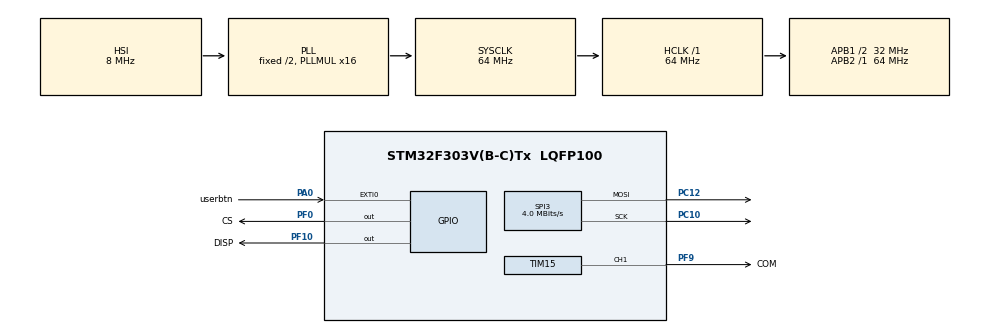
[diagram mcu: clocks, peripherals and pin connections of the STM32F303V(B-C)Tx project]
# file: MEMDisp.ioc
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Mcu.Family=STM32F3
Mcu.Name=STM32F303V(B-C)Tx
Mcu.Package=LQFP100
NVIC.EXTI0_IRQn=true\:0\:0\:false\:false\:true\:true\:true
NVIC.PriorityGroup=NVIC_PRIORITYGROUP_0
PA0.GPIO_Label=userbtn
PA0.Signal=GPXTI0
PA13.Signal=SYS_JTMS-SWDIO
PA14.Signal=SYS_JTCK-SWCLK
PB3.Signal=SYS_JTDO-TRACESWO
PC10.Mode=TX_Only_Simplex_Unidirect_Master
PC10.Signal=SPI3_SCK
PC12.Mode=TX_Only_Simplex_Unidirect_Master
PC12.Signal=SPI3_MOSI
PF0-OSC_IN.GPIO_Label=CS
PF0-OSC_IN.Signal=GPIO_Output
PF10.GPIO_Label=DISP
PF10.Signal=GPIO_Output
PF9.GPIO_Label=COM
PF9.GPIO_Speed=GPIO_SPEED_FREQ_HIGH
PF9.Signal=S_TIM15_CH1
ProjectManager.HeapSize=0x200
ProjectManager.StackSize=0x400
ProjectManager.TargetToolchain=STM32CubeIDE
RCC.AHBFreq_Value=64000000
RCC.APB1CLKDivider=RCC_HCLK_DIV2
RCC.APB1Freq_Value=32000000
RCC.APB1TimFreq_Value=64000000
RCC.APB2Freq_Value=64000000
RCC.APB2TimFreq_Value=64000000
RCC.CortexFreq_Value=64000000
RCC.HCLKFreq_Value=64000000
RCC.HSE_VALUE=8000000
RCC.HSI_VALUE=8000000
RCC.LSE_VALUE=32768
RCC.PLLMUL=RCC_PLL_MUL16
RCC.SYSCLKFreq_VALUE=64000000
RCC.SYSCLKSourceVirtual=RCC_SYSCLKSOURCE_PLLCLK
RCC.USBFreq_Value=64000000
SH.S_TIM15_CH1.0=TIM15_CH1,PWM Generation1 CH1
SPI3.BaudRatePrescaler=SPI_BAUDRATEPRESCALER_8
SPI3.CalculateBaudRate=4.0 MBits/s
SPI3.DataSize=SPI_DATASIZE_8BIT
SPI3.Direction=SPI_DIRECTION_2LINES
SPI3.FirstBit=SPI_FIRSTBIT_MSB
SPI3.Mode=SPI_MODE_MASTER
SPI3.NSSPMode=SPI_NSS_PULSE_DISABLE
SPI3.TIMode=SPI_TIMODE_DISABLE
SPI3.VirtualType=VM_MASTER
TIM15.AutoReloadPreload=TIM_AUTORELOAD_PRELOAD_DISABLE
TIM15.Channel-PWM\ Generation1\ CH1=TIM_CHANNEL_1
TIM15.Period=20 - 1
TIM15.Prescaler=64000-1
VP_TIM15_VS_ClockSourceINT.Mode=Internal
board=STM32F3DISCOVERY

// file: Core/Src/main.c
/* USER CODE BEGIN Header */
/**
  ******************************************************************************
  * @file           : main.c
  * @brief          : Main program body
  ******************************************************************************
  * @attention
  *
  * <h2><center>&copy; Copyright (c) 2020 STMicroelectronics.
  * All rights reserved.</center></h2>
  *
  * This software component is licensed by ST under BSD 3-Clause license,
  * the "License"; You may not use this file except in compliance with the
  * License. You may obtain a copy of the License at:
  *                        opensource.org/licenses/BSD-3-Clause
  *
  ******************************************************************************
  */
/* USER CODE END Header */
#include "main.h"

/* USER CODE BEGIN Includes */
#include "LS027B7DH01.h"
#include "Image.h"
#include "Image2.h"
/* USER CODE END Includes */

/* USER CODE BEGIN PTD */
LS027B7DH01 MemDisp;
/* USER CODE END PTD */

SPI_HandleTypeDef hspi3;

TIM_HandleTypeDef htim15;

/* USER CODE BEGIN PV */
uint8_t swCase,itCall;
/* USER CODE END PV */

void SystemClock_Config(void);
static void MX_GPIO_Init(void);
static void MX_SPI3_Init(void);
static void MX_TIM15_Init(void);

int main(void)
{

  /* MCU Configuration--------------------------------------------------------*/

  /* Reset of all peripherals, Initializes the Flash interface and the Systick. */
  HAL_Init();

  /* Configure the system clock */
  SystemClock_Config();

  /* Initialize all configured peripherals */
  MX_GPIO_Init();
  MX_SPI3_Init();
  MX_TIM15_Init();
  /* USER CODE BEGIN 2 */
  /* Pinout (MCU -> Display)
   * PC10 -> SCLK
   * PC12 -> SI
   * PF0  -> SCS
   * PF9  -> EXTCOMIN
   * PF10 -> DISP
   */
  // ALL GPIO AND BUSES MUST BE INITED BEFORE CALL THIS FUNCTION
  LCD_Init(&MemDisp,&hspi3,GPIOF,CS_Pin,DISP_Pin,&htim15,TIM_CHANNEL_1);
  HAL_Delay(1000);

  /* USER CODE END 2 */

  /* Infinite loop */
  while (1)
  {
	 if(itCall !=0){
	  switch(swCase){

	  	case 0:
	  		  LCD_BufClean();
	  		  LCD_Clean(&MemDisp);
	  		  itCall = 0;
	  		  break;
	  	case 1:
	  		  LCD_LoadFull((uint8_t *)Disney);
	  		  HAL_Delay(100);
	  		  LCD_Update(&MemDisp);
	  		  itCall = 0;
	  		  break;
	  	case 2:
	  		  LCD_Fill(true);
	  		  LCD_Update(&MemDisp);
	  		  itCall = 0;
	  		  break;
	  	case 3:
	  		  LCD_LoadPart((uint8_t *)GawrGura,10,1,30,240); //Sauce : @NotSafeForCode
	  		  HAL_Delay(100);
	  		  LCD_Update(&MemDisp);
	  		  itCall = 0;
	  		  break;
	  	case 4:
	  		  LCD_BufClean();
	  		  LCD_Clean(&MemDisp);
	  		  itCall = 0;
	  		  break;

	  	case 5:
	  		  LCD_Print("This is \nLS027B7DH01 !",21);
	  		  HAL_Delay(10);
	  		  LCD_Update(&MemDisp);
	  		  itCall = 0;
	  		  break;
	  	case 6:
	  		  LCD_Invert();
	  		  LCD_Update(&MemDisp);
	  		  itCall = 0;
	  		  break;
	  	case 7:
	  		  LCD_Print("\nCoded By TinLethax!",21);
	  		  HAL_Delay(10);
	  		  LCD_Update(&MemDisp);
	  		  itCall = 0;
	  		  swCase = 0;
	  		  break;
	  	default:
	  		break;
	  	}
	 }
  }
}

void SystemClock_Config(void)
{
  RCC_OscInitTypeDef RCC_OscInitStruct = {0};
  RCC_ClkInitTypeDef RCC_ClkInitStruct = {0};

  /** Initializes the RCC Oscillators according to the specified parameters
  * in the RCC_OscInitTypeDef structure.
  */
  RCC_OscInitStruct.OscillatorType = RCC_OSCILLATORTYPE_HSI;
  RCC_OscInitStruct.HSIState = RCC_HSI_ON;
  RCC_OscInitStruct.HSICalibrationValue = RCC_HSICALIBRATION_DEFAULT;
  RCC_OscInitStruct.PLL.PLLState = RCC_PLL_ON;
  RCC_OscInitStruct.PLL.PLLSource = RCC_PLLSOURCE_HSI;
  RCC_OscInitStruct.PLL.PLLMUL = RCC_PLL_MUL16;
  if (HAL_RCC_OscConfig(&RCC_OscInitStruct) != HAL_OK)
  {
    Error_Handler();
  }
  /** Initializes the CPU, AHB and APB buses clocks
  */
  RCC_ClkInitStruct.ClockType = RCC_CLOCKTYPE_HCLK|RCC_CLOCKTYPE_SYSCLK
                              |RCC_CLOCKTYPE_PCLK1|RCC_CLOCKTYPE_PCLK2;
  RCC_ClkInitStruct.SYSCLKSource = RCC_SYSCLKSOURCE_PLLCLK;
  RCC_ClkInitStruct.AHBCLKDivider = RCC_SYSCLK_DIV1;
  RCC_ClkInitStruct.APB1CLKDivider = RCC_HCLK_DIV2;
  RCC_ClkInitStruct.APB2CLKDivider = RCC_HCLK_DIV1;

  if (HAL_RCC_ClockConfig(&RCC_ClkInitStruct, FLASH_LATENCY_2) != HAL_OK)
  {
    Error_Handler();
  }
}

static void MX_SPI3_Init(void)
{

  /* SPI3 parameter configuration*/
  hspi3.Instance = SPI3;
  hspi3.Init.Mode = SPI_MODE_MASTER;
  hspi3.Init.Direction = SPI_DIRECTION_2LINES;
  hspi3.Init.DataSize = SPI_DATASIZE_8BIT;
  hspi3.Init.CLKPolarity = SPI_POLARITY_LOW;
  hspi3.Init.CLKPhase = SPI_PHASE_1EDGE;
  hspi3.Init.NSS = SPI_NSS_SOFT;
  hspi3.Init.BaudRatePrescaler = SPI_BAUDRATEPRESCALER_8;
  hspi3.Init.FirstBit = SPI_FIRSTBIT_MSB;
  hspi3.Init.TIMode = SPI_TIMODE_DISABLE;
  hspi3.Init.CRCCalculation = SPI_CRCCALCULATION_DISABLE;
  hspi3.Init.CRCPolynomial = 7;
  hspi3.Init.CRCLength = SPI_CRC_LENGTH_DATASIZE;
  hspi3.Init.NSSPMode = SPI_NSS_PULSE_DISABLE;
  if (HAL_SPI_Init(&hspi3) != HAL_OK)
  {
    Error_Handler();
  }

}

static void MX_TIM15_Init(void)
{

  TIM_ClockConfigTypeDef sClockSourceConfig = {0};
  TIM_MasterConfigTypeDef sMasterConfig = {0};
  TIM_OC_InitTypeDef sConfigOC = {0};
  TIM_BreakDeadTimeConfigTypeDef sBreakDeadTimeConfig = {0};

  htim15.Instance = TIM15;
  htim15.Init.Prescaler = 64000-1;
  htim15.Init.CounterMode = TIM_COUNTERMODE_UP;
  htim15.Init.Period = 20 - 1;
  htim15.Init.ClockDivision = TIM_CLOCKDIVISION_DIV1;
  htim15.Init.RepetitionCounter = 0;
  htim15.Init.AutoReloadPreload = TIM_AUTORELOAD_PRELOAD_DISABLE;
  if (HAL_TIM_Base_Init(&htim15) != HAL_OK)
  {
    Error_Handler();
  }
  sClockSourceConfig.ClockSource = TIM_CLOCKSOURCE_INTERNAL;
  if (HAL_TIM_ConfigClockSource(&htim15, &sClockSourceConfig) != HAL_OK)
  {
    Error_Handler();
  }
  if (HAL_TIM_PWM_Init(&htim15) != HAL_OK)
  {
    Error_Handler();
  }
  sMasterConfig.MasterOutputTrigger = TIM_TRGO_RESET;
  sMasterConfig.MasterSlaveMode = TIM_MASTERSLAVEMODE_DISABLE;
  if (HAL_TIMEx_MasterConfigSynchronization(&htim15, &sMasterConfig) != HAL_OK)
  {
    Error_Handler();
  }
  sConfigOC.OCMode = TIM_OCMODE_PWM1;
  sConfigOC.Pulse = 0;
  sConfigOC.OCPolarity = TIM_OCPOLARITY_HIGH;
  sConfigOC.OCNPolarity = TIM_OCNPOLARITY_HIGH;
  sConfigOC.OCFastMode = TIM_OCFAST_DISABLE;
  sConfigOC.OCIdleState = TIM_OCIDLESTATE_RESET;
  sConfigOC.OCNIdleState = TIM_OCNIDLESTATE_RESET;
  if (HAL_TIM_PWM_ConfigChannel(&htim15, &sConfigOC, TIM_CHANNEL_1) != HAL_OK)
  {
    Error_Handler();
  }
  sBreakDeadTimeConfig.OffStateRunMode = TIM_OSSR_DISABLE;
  sBreakDeadTimeConfig.OffStateIDLEMode = TIM_OSSI_DISABLE;
  sBreakDeadTimeConfig.LockLevel = TIM_LOCKLEVEL_OFF;
  sBreakDeadTimeConfig.DeadTime = 0;
  sBreakDeadTimeConfig.BreakState = TIM_BREAK_DISABLE;
  sBreakDeadTimeConfig.BreakPolarity = TIM_BREAKPOLARITY_HIGH;
  sBreakDeadTimeConfig.BreakFilter = 0;
  sBreakDeadTimeConfig.AutomaticOutput = TIM_AUTOMATICOUTPUT_DISABLE;
  if (HAL_TIMEx_ConfigBreakDeadTime(&htim15, &sBreakDeadTimeConfig) != HAL_OK)
  {
    Error_Handler();
  }
  HAL_TIM_MspPostInit(&htim15);

}

static void MX_GPIO_Init(void)
{
  GPIO_InitTypeDef GPIO_InitStruct = {0};

  /* GPIO Ports Clock Enable */
  __HAL_RCC_GPIOF_CLK_ENABLE();
  __HAL_RCC_GPIOA_CLK_ENABLE();
  __HAL_RCC_GPIOC_CLK_ENABLE();
  __HAL_RCC_GPIOB_CLK_ENABLE();

  /*Configure GPIO pin Output Level */
  HAL_GPIO_WritePin(GPIOF, DISP_Pin|CS_Pin, GPIO_PIN_RESET);

  /*Configure GPIO pins : DISP_Pin CS_Pin */
  GPIO_InitStruct.Pin = DISP_Pin|CS_Pin;
  GPIO_InitStruct.Mode = GPIO_MODE_OUTPUT_PP;
  GPIO_InitStruct.Pull = GPIO_NOPULL;
  GPIO_InitStruct.Speed = GPIO_SPEED_FREQ_LOW;
  HAL_GPIO_Init(GPIOF, &GPIO_InitStruct);

  /*Configure GPIO pin : userbtn_Pin */
  GPIO_InitStruct.Pin = userbtn_Pin;
  GPIO_InitStruct.Mode = GPIO_MODE_IT_RISING;
  GPIO_InitStruct.Pull = GPIO_NOPULL;
  HAL_GPIO_Init(userbtn_GPIO_Port, &GPIO_InitStruct);

  /* EXTI interrupt init*/
  HAL_NVIC_SetPriority(EXTI0_IRQn, 0, 0);
  HAL_NVIC_EnableIRQ(EXTI0_IRQn);

}

/* USER CODE BEGIN 4 */
void HAL_GPIO_EXTI_Callback(uint16_t GPIO_Pin){
	if(GPIO_Pin == GPIO_PIN_0){
	itCall = 1;
	swCase++;
	if (swCase > 7) swCase = 0;
  }
}
/* USER CODE END 4 */

void Error_Handler(void)
{
  __disable_irq();
  while (1)
  {
  }
}

/************************ (C) COPYRIGHT STMicroelectronics *****END OF FILE****/
